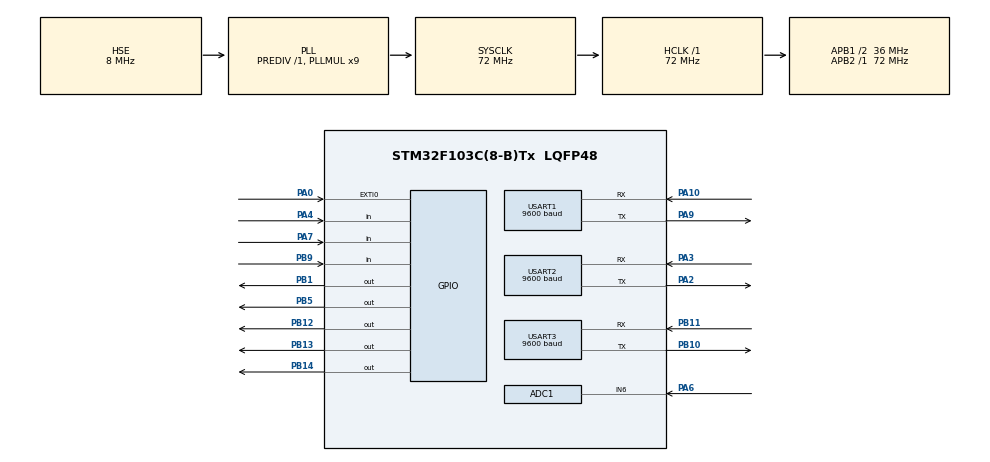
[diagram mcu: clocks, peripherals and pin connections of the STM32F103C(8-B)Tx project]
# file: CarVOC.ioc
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ADC1.Channel-0\#ChannelRegularConversion=ADC_CHANNEL_6
ADC1.ContinuousConvMode=DISABLE
ADC1.DataAlign=ADC_DATAALIGN_RIGHT
ADC1.DiscontinuousConvMode=DISABLE
ADC1.EnableAnalogWatchDog=false
ADC1.EnableRegularConversion=ENABLE
ADC1.ExternalTrigConv=ADC_SOFTWARE_START
ADC1.InjNumberOfConversion=0
ADC1.NbrOfConversion=1
ADC1.NbrOfConversionFlag=1
ADC1.Rank-0\#ChannelRegularConversion=1
ADC1.SamplingTime-0\#ChannelRegularConversion=ADC_SAMPLETIME_1CYCLE_5
ADC1.ScanConvMode=ADC_SCAN_DISABLE
ADC1.master=1
Dma.Request0=USART1_TX
Dma.Request1=USART2_TX
Dma.Request2=USART3_TX
Dma.USART1_TX.0.Direction=DMA_MEMORY_TO_PERIPH
Dma.USART1_TX.0.Instance=DMA1_Channel4
Dma.USART1_TX.0.MemDataAlignment=DMA_MDATAALIGN_BYTE
Dma.USART1_TX.0.MemInc=DMA_MINC_ENABLE
Dma.USART1_TX.0.Mode=DMA_NORMAL
Dma.USART1_TX.0.PeriphDataAlignment=DMA_PDATAALIGN_BYTE
Dma.USART1_TX.0.PeriphInc=DMA_PINC_DISABLE
Dma.USART1_TX.0.Priority=DMA_PRIORITY_MEDIUM
Dma.USART2_TX.1.Direction=DMA_MEMORY_TO_PERIPH
Dma.USART2_TX.1.Instance=DMA1_Channel7
Dma.USART2_TX.1.MemDataAlignment=DMA_MDATAALIGN_BYTE
Dma.USART2_TX.1.MemInc=DMA_MINC_ENABLE
Dma.USART2_TX.1.Mode=DMA_NORMAL
Dma.USART2_TX.1.PeriphDataAlignment=DMA_PDATAALIGN_BYTE
Dma.USART2_TX.1.PeriphInc=DMA_PINC_DISABLE
Dma.USART2_TX.1.Priority=DMA_PRIORITY_MEDIUM
Dma.USART3_TX.2.Direction=DMA_MEMORY_TO_PERIPH
Dma.USART3_TX.2.Instance=DMA1_Channel2
Dma.USART3_TX.2.MemDataAlignment=DMA_MDATAALIGN_BYTE
Dma.USART3_TX.2.MemInc=DMA_MINC_ENABLE
Dma.USART3_TX.2.Mode=DMA_NORMAL
Dma.USART3_TX.2.PeriphDataAlignment=DMA_PDATAALIGN_BYTE
Dma.USART3_TX.2.PeriphInc=DMA_PINC_DISABLE
Dma.USART3_TX.2.Priority=DMA_PRIORITY_MEDIUM
FREERTOS.Tasks01=defaultTask,0,128,StartDefaultTask,Default,NULL
FREERTOS.configTOTAL_HEAP_SIZE=13312
IWDG.Prescaler=IWDG_PRESCALER_8
IWDG.Reload=2500
Mcu.Family=STM32F1
Mcu.Name=STM32F103C(8-B)Tx
Mcu.Package=LQFP48
NVIC.DMA1_Channel2_IRQn=true\:5\:0\:false\:false\:true\:true\:false
NVIC.DMA1_Channel4_IRQn=true\:5\:0\:false\:false\:true\:true\:false
NVIC.DMA1_Channel7_IRQn=true\:5\:0\:false\:false\:true\:true\:false
NVIC.EXTI0_IRQn=true\:6\:0\:true\:true\:true\:1\:true\:true
NVIC.PriorityGroup=NVIC_PRIORITYGROUP_4
NVIC.TIM2_IRQn=true\:9\:0\:true\:true\:true\:5\:true\:true
NVIC.USART1_IRQn=true\:5\:0\:true\:true\:true\:3\:true\:true
NVIC.USART2_IRQn=true\:7\:0\:true\:true\:true\:4\:true\:true
NVIC.USART3_IRQn=true\:6\:0\:true\:true\:true\:6\:true\:true
PA0-WKUP.GPIO_ModeDefaultEXTI=GPIO_MODE_IT_RISING_FALLING
PA0-WKUP.GPIO_PuPd=GPIO_PULLUP
PA0-WKUP.Signal=GPXTI0
PA10.Mode=Asynchronous
PA10.Signal=USART1_RX
PA13.Mode=Trace_Asynchronous_SW
PA13.Signal=SYS_JTMS-SWDIO
PA14.Mode=Trace_Asynchronous_SW
PA14.Signal=SYS_JTCK-SWCLK
PA2.Mode=Asynchronous
PA2.Signal=USART2_TX
PA3.Mode=Asynchronous
PA3.Signal=USART2_RX
PA4.GPIO_PuPd=GPIO_PULLUP
PA4.Signal=GPIO_Input
PA6.Signal=ADCx_IN6
PA7.GPIO_PuPd=GPIO_PULLUP
PA7.Signal=GPIO_Input
PA9.Mode=Asynchronous
PA9.Signal=USART1_TX
PB1.GPIO_ModeDefaultOutputPP=GPIO_MODE_OUTPUT_PP
PB1.GPIO_PuPd=GPIO_NOPULL
PB1.GPIO_Speed=GPIO_SPEED_FREQ_MEDIUM
PB1.PinState=GPIO_PIN_RESET
PB1.Signal=GPIO_Output
PB10.Mode=Asynchronous
PB10.Signal=USART3_TX
PB11.Mode=Asynchronous
PB11.Signal=USART3_RX
PB12.GPIO_Speed=GPIO_SPEED_FREQ_MEDIUM
PB12.Signal=GPIO_Output
PB13.GPIO_Speed=GPIO_SPEED_FREQ_MEDIUM
PB13.Signal=GPIO_Output
PB14.GPIO_Speed=GPIO_SPEED_FREQ_MEDIUM
PB14.Signal=GPIO_Output
PB3.Mode=Trace_Asynchronous_SW
PB3.Signal=SYS_JTDO-TRACESWO
PB5.Signal=GPIO_Output
PB9.GPIO_PuPd=GPIO_PULLUP
PB9.Signal=GPIO_Input
PD0-OSC_IN.Mode=HSE-External-Oscillator
PD0-OSC_IN.Signal=RCC_OSC_IN
PD1-OSC_OUT.Mode=HSE-External-Oscillator
PD1-OSC_OUT.Signal=RCC_OSC_OUT
ProjectManager.HeapSize=0x200
ProjectManager.StackSize=0x400
ProjectManager.TargetToolchain=MDK-ARM V5
RCC.ADCPresc=RCC_ADCPCLK2_DIV6
RCC.AHBFreq_Value=72000000
RCC.APB1CLKDivider=RCC_HCLK_DIV2
RCC.APB1Freq_Value=36000000
RCC.APB1TimFreq_Value=72000000
RCC.APB2Freq_Value=72000000
RCC.APB2TimFreq_Value=72000000
RCC.HCLKFreq_Value=72000000
RCC.PLLMUL=RCC_PLL_MUL9
RCC.PLLSourceVirtual=RCC_PLLSOURCE_HSE
RCC.SYSCLKFreq_VALUE=72000000
RCC.SYSCLKSource=RCC_SYSCLKSOURCE_PLLCLK
RCC.USBFreq_Value=72000000
SH.ADCx_IN6.0=ADC1_IN6,IN6
TIM2.AutoReloadPreload=TIM_AUTORELOAD_PRELOAD_ENABLE
TIM2.Period=720-1
TIM2.Prescaler=1-1
USART1.BaudRate=9600
USART1.VirtualMode=VM_ASYNC
USART2.BaudRate=9600
USART2.VirtualMode=VM_ASYNC
USART3.BaudRate=9600
USART3.VirtualMode=VM_ASYNC
VP_FREERTOS_VS_ENABLE.Mode=Enabled
VP_IWDG_VS_IWDG.Mode=IWDG_Activate
VP_TIM2_VS_ClockSourceINT.Mode=Internal
board=MavSword

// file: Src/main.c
/**
  ******************************************************************************
  * @file           : main.c
  * @brief          : Main program body
  ******************************************************************************
  * This notice applies to any and all portions of this file
  * that are not between comment pairs USER CODE BEGIN and
  * USER CODE END. Other portions of this file, whether
  * inserted by the user or by software development tools
  * are owned by their respective copyright owners.
  *
  * Copyright (c) 2019 STMicroelectronics International N.V.
  * All rights reserved.
  *
  * Redistribution and use in source and binary forms, with or without
  * modification, are permitted, provided that the following conditions are met:
  *
  * 1. Redistribution of source code must retain the above copyright notice,
  *    this list of conditions and the following disclaimer.
  * 2. Redistributions in binary form must reproduce the above copyright notice,
  *    this list of conditions and the following disclaimer in the documentation
  *    and/or other materials provided with the distribution.
  * 3. Neither the name of STMicroelectronics nor the names of other
  *    contributors to this software may be used to endorse or promote products
  *    derived from this software without specific written permission.
  * 4. This software, including modifications and/or derivative works of this
  *    software, must execute solely and exclusively on microcontroller or
  *    microprocessor devices manufactured by or for STMicroelectronics.
  * 5. Redistribution and use of this software other than as permitted under
  *    this license is void and will automatically terminate your rights under
  *    this license.
  *
  * THIS SOFTWARE IS PROVIDED BY STMICROELECTRONICS AND CONTRIBUTORS "AS IS"
  * AND ANY EXPRESS, IMPLIED OR STATUTORY WARRANTIES, INCLUDING, BUT NOT
  * LIMITED TO, THE IMPLIED WARRANTIES OF MERCHANTABILITY, FITNESS FOR A
  * PARTICULAR PURPOSE AND NON-INFRINGEMENT OF THIRD PARTY INTELLECTUAL PROPERTY
  * RIGHTS ARE DISCLAIMED TO THE FULLEST EXTENT PERMITTED BY LAW. IN NO EVENT
  * SHALL STMICROELECTRONICS OR CONTRIBUTORS BE LIABLE FOR ANY DIRECT, INDIRECT,
  * INCIDENTAL, SPECIAL, EXEMPLARY, OR CONSEQUENTIAL DAMAGES (INCLUDING, BUT NOT
  * LIMITED TO, PROCUREMENT OF SUBSTITUTE GOODS OR SERVICES; LOSS OF USE, DATA,
  * OR PROFITS; OR BUSINESS INTERRUPTION) HOWEVER CAUSED AND ON ANY THEORY OF
  * LIABILITY, WHETHER IN CONTRACT, STRICT LIABILITY, OR TORT (INCLUDING
  * NEGLIGENCE OR OTHERWISE) ARISING IN ANY WAY OUT OF THE USE OF THIS SOFTWARE,
  * EVEN IF ADVISED OF THE POSSIBILITY OF SUCH DAMAGE.
  *
  ******************************************************************************
  */
#include "main.h"
#include "stm32f1xx_hal.h"
#include "cmsis_os.h"

/* USER CODE BEGIN Includes */
#include "UserTask.h"
/* USER CODE END Includes */

ADC_HandleTypeDef hadc1;

IWDG_HandleTypeDef hiwdg;

TIM_HandleTypeDef htim2;

UART_HandleTypeDef huart1;
UART_HandleTypeDef huart2;
UART_HandleTypeDef huart3;
DMA_HandleTypeDef hdma_usart1_tx;
DMA_HandleTypeDef hdma_usart2_tx;
DMA_HandleTypeDef hdma_usart3_tx;

osThreadId defaultTaskHandle;

/* USER CODE BEGIN PV */
/* Private variables ---------------------------------------------------------*/

/* USER CODE END PV */

void SystemClock_Config(void);
static void MX_GPIO_Init(void);
static void MX_DMA_Init(void);
static void MX_USART1_UART_Init(void);
static void MX_USART2_UART_Init(void);
static void MX_IWDG_Init(void);
static void MX_TIM2_Init(void);
static void MX_USART3_UART_Init(void);
static void MX_ADC1_Init(void);
void StartDefaultTask(void const * argument);
static void MX_NVIC_Init(void);

/* USER CODE BEGIN PFP */
/* Private function prototypes -----------------------------------------------*/

/* USER CODE END PFP */

int main(void)
{

  /* MCU Configuration----------------------------------------------------------*/

  /* Reset of all peripherals, Initializes the Flash interface and the Systick. */
  HAL_Init();

  /* Configure the system clock */
  SystemClock_Config();

  /* Initialize all configured peripherals */
  MX_GPIO_Init();
  MX_DMA_Init();
  MX_USART1_UART_Init();
  MX_USART2_UART_Init();
  MX_IWDG_Init();
  MX_TIM2_Init();
  MX_USART3_UART_Init();
  MX_ADC1_Init();

  /* Initialize interrupts */
  MX_NVIC_Init();

  /* Create the thread(s) */
  /* definition and creation of defaultTask */
  osThreadDef(defaultTask, StartDefaultTask, osPriorityNormal, 0, 128);
  defaultTaskHandle = osThreadCreate(osThread(defaultTask), NULL);

  /* USER CODE BEGIN RTOS_THREADS */
  /* add threads, ... */
	app_run();
  /* USER CODE END RTOS_THREADS */

  /* Start scheduler */
  osKernelStart();

  /* We should never get here as control is now taken by the scheduler */

  /* Infinite loop */
  while (1)
  {

  }

}

void SystemClock_Config(void)
{

  RCC_OscInitTypeDef RCC_OscInitStruct;
  RCC_ClkInitTypeDef RCC_ClkInitStruct;
  RCC_PeriphCLKInitTypeDef PeriphClkInit;

    /**Initializes the CPU, AHB and APB busses clocks
    */
  RCC_OscInitStruct.OscillatorType = RCC_OSCILLATORTYPE_LSI|RCC_OSCILLATORTYPE_HSE;
  RCC_OscInitStruct.HSEState = RCC_HSE_ON;
  RCC_OscInitStruct.HSEPredivValue = RCC_HSE_PREDIV_DIV1;
  RCC_OscInitStruct.HSIState = RCC_HSI_ON;
  RCC_OscInitStruct.LSIState = RCC_LSI_ON;
  RCC_OscInitStruct.PLL.PLLState = RCC_PLL_ON;
  RCC_OscInitStruct.PLL.PLLSource = RCC_PLLSOURCE_HSE;
  RCC_OscInitStruct.PLL.PLLMUL = RCC_PLL_MUL9;
  if (HAL_RCC_OscConfig(&RCC_OscInitStruct) != HAL_OK)
  {
    _Error_Handler(__FILE__, __LINE__);
  }

    /**Initializes the CPU, AHB and APB busses clocks
    */
  RCC_ClkInitStruct.ClockType = RCC_CLOCKTYPE_HCLK|RCC_CLOCKTYPE_SYSCLK
                              |RCC_CLOCKTYPE_PCLK1|RCC_CLOCKTYPE_PCLK2;
  RCC_ClkInitStruct.SYSCLKSource = RCC_SYSCLKSOURCE_PLLCLK;
  RCC_ClkInitStruct.AHBCLKDivider = RCC_SYSCLK_DIV1;
  RCC_ClkInitStruct.APB1CLKDivider = RCC_HCLK_DIV2;
  RCC_ClkInitStruct.APB2CLKDivider = RCC_HCLK_DIV1;

  if (HAL_RCC_ClockConfig(&RCC_ClkInitStruct, FLASH_LATENCY_2) != HAL_OK)
  {
    _Error_Handler(__FILE__, __LINE__);
  }

  PeriphClkInit.PeriphClockSelection = RCC_PERIPHCLK_ADC;
  PeriphClkInit.AdcClockSelection = RCC_ADCPCLK2_DIV6;
  if (HAL_RCCEx_PeriphCLKConfig(&PeriphClkInit) != HAL_OK)
  {
    _Error_Handler(__FILE__, __LINE__);
  }

    /**Configure the Systick interrupt time
    */
  HAL_SYSTICK_Config(HAL_RCC_GetHCLKFreq()/1000);

    /**Configure the Systick
    */
  HAL_SYSTICK_CLKSourceConfig(SYSTICK_CLKSOURCE_HCLK);

  /* SysTick_IRQn interrupt configuration */
  HAL_NVIC_SetPriority(SysTick_IRQn, 15, 0);
}

/**
  * @brief NVIC Configuration.
  * @retval None
  */
static void MX_NVIC_Init(void)
{
  /* EXTI0_IRQn interrupt configuration */
  HAL_NVIC_SetPriority(EXTI0_IRQn, 6, 0);
  HAL_NVIC_EnableIRQ(EXTI0_IRQn);
  /* USART1_IRQn interrupt configuration */
  HAL_NVIC_SetPriority(USART1_IRQn, 5, 0);
  HAL_NVIC_EnableIRQ(USART1_IRQn);
  /* USART2_IRQn interrupt configuration */
  HAL_NVIC_SetPriority(USART2_IRQn, 7, 0);
  HAL_NVIC_EnableIRQ(USART2_IRQn);
  /* TIM2_IRQn interrupt configuration */
  HAL_NVIC_SetPriority(TIM2_IRQn, 9, 0);
  HAL_NVIC_EnableIRQ(TIM2_IRQn);
  /* USART3_IRQn interrupt configuration */
  HAL_NVIC_SetPriority(USART3_IRQn, 6, 0);
  HAL_NVIC_EnableIRQ(USART3_IRQn);
}

/* ADC1 init function */
static void MX_ADC1_Init(void)
{

  ADC_ChannelConfTypeDef sConfig;

    /**Common config
    */
  hadc1.Instance = ADC1;
  hadc1.Init.ScanConvMode = ADC_SCAN_DISABLE;
  hadc1.Init.ContinuousConvMode = DISABLE;
  hadc1.Init.DiscontinuousConvMode = DISABLE;
  hadc1.Init.ExternalTrigConv = ADC_SOFTWARE_START;
  hadc1.Init.DataAlign = ADC_DATAALIGN_RIGHT;
  hadc1.Init.NbrOfConversion = 1;
  if (HAL_ADC_Init(&hadc1) != HAL_OK)
  {
    _Error_Handler(__FILE__, __LINE__);
  }

    /**Configure Regular Channel
    */
  sConfig.Channel = ADC_CHANNEL_6;
  sConfig.Rank = ADC_REGULAR_RANK_1;
  sConfig.SamplingTime = ADC_SAMPLETIME_1CYCLE_5;
  if (HAL_ADC_ConfigChannel(&hadc1, &sConfig) != HAL_OK)
  {
    _Error_Handler(__FILE__, __LINE__);
  }

}

/* IWDG init function */
static void MX_IWDG_Init(void)
{

  hiwdg.Instance = IWDG;
  hiwdg.Init.Prescaler = IWDG_PRESCALER_8;
  hiwdg.Init.Reload = 2500;
  if (HAL_IWDG_Init(&hiwdg) != HAL_OK)
  {
    _Error_Handler(__FILE__, __LINE__);
  }

}

/* TIM2 init function */
static void MX_TIM2_Init(void)
{

  TIM_ClockConfigTypeDef sClockSourceConfig;
  TIM_MasterConfigTypeDef sMasterConfig;

  htim2.Instance = TIM2;
  htim2.Init.Prescaler = 1-1;
  htim2.Init.CounterMode = TIM_COUNTERMODE_UP;
  htim2.Init.Period = 720-1;
  htim2.Init.ClockDivision = TIM_CLOCKDIVISION_DIV1;
  htim2.Init.AutoReloadPreload = TIM_AUTORELOAD_PRELOAD_ENABLE;
  if (HAL_TIM_Base_Init(&htim2) != HAL_OK)
  {
    _Error_Handler(__FILE__, __LINE__);
  }

  sClockSourceConfig.ClockSource = TIM_CLOCKSOURCE_INTERNAL;
  if (HAL_TIM_ConfigClockSource(&htim2, &sClockSourceConfig) != HAL_OK)
  {
    _Error_Handler(__FILE__, __LINE__);
  }

  sMasterConfig.MasterOutputTrigger = TIM_TRGO_RESET;
  sMasterConfig.MasterSlaveMode = TIM_MASTERSLAVEMODE_DISABLE;
  if (HAL_TIMEx_MasterConfigSynchronization(&htim2, &sMasterConfig) != HAL_OK)
  {
    _Error_Handler(__FILE__, __LINE__);
  }

}

/* USART1 init function */
static void MX_USART1_UART_Init(void)
{

  huart1.Instance = USART1;
  huart1.Init.BaudRate = 9600;
  huart1.Init.WordLength = UART_WORDLENGTH_8B;
  huart1.Init.StopBits = UART_STOPBITS_1;
  huart1.Init.Parity = UART_PARITY_NONE;
  huart1.Init.Mode = UART_MODE_TX_RX;
  huart1.Init.HwFlowCtl = UART_HWCONTROL_NONE;
  huart1.Init.OverSampling = UART_OVERSAMPLING_16;
  if (HAL_UART_Init(&huart1) != HAL_OK)
  {
    _Error_Handler(__FILE__, __LINE__);
  }

}

/* USART2 init function */
static void MX_USART2_UART_Init(void)
{

  huart2.Instance = USART2;
  huart2.Init.BaudRate = 9600;
  huart2.Init.WordLength = UART_WORDLENGTH_8B;
  huart2.Init.StopBits = UART_STOPBITS_1;
  huart2.Init.Parity = UART_PARITY_NONE;
  huart2.Init.Mode = UART_MODE_TX_RX;
  huart2.Init.HwFlowCtl = UART_HWCONTROL_NONE;
  huart2.Init.OverSampling = UART_OVERSAMPLING_16;
  if (HAL_UART_Init(&huart2) != HAL_OK)
  {
    _Error_Handler(__FILE__, __LINE__);
  }

}

/* USART3 init function */
static void MX_USART3_UART_Init(void)
{

  huart3.Instance = USART3;
  huart3.Init.BaudRate = 9600;
  huart3.Init.WordLength = UART_WORDLENGTH_8B;
  huart3.Init.StopBits = UART_STOPBITS_1;
  huart3.Init.Parity = UART_PARITY_NONE;
  huart3.Init.Mode = UART_MODE_TX_RX;
  huart3.Init.HwFlowCtl = UART_HWCONTROL_NONE;
  huart3.Init.OverSampling = UART_OVERSAMPLING_16;
  if (HAL_UART_Init(&huart3) != HAL_OK)
  {
    _Error_Handler(__FILE__, __LINE__);
  }

}

static void MX_DMA_Init(void)
{
  /* DMA controller clock enable */
  __HAL_RCC_DMA1_CLK_ENABLE();

  /* DMA interrupt init */
  /* DMA1_Channel2_IRQn interrupt configuration */
  HAL_NVIC_SetPriority(DMA1_Channel2_IRQn, 5, 0);
  HAL_NVIC_EnableIRQ(DMA1_Channel2_IRQn);
  /* DMA1_Channel4_IRQn interrupt configuration */
  HAL_NVIC_SetPriority(DMA1_Channel4_IRQn, 5, 0);
  HAL_NVIC_EnableIRQ(DMA1_Channel4_IRQn);
  /* DMA1_Channel7_IRQn interrupt configuration */
  HAL_NVIC_SetPriority(DMA1_Channel7_IRQn, 5, 0);
  HAL_NVIC_EnableIRQ(DMA1_Channel7_IRQn);

}

/** Configure pins as
        * Analog
        * Input
        * Output
        * EVENT_OUT
        * EXTI
*/
static void MX_GPIO_Init(void)
{

  GPIO_InitTypeDef GPIO_InitStruct;

  /* GPIO Ports Clock Enable */
  __HAL_RCC_GPIOD_CLK_ENABLE();
  __HAL_RCC_GPIOA_CLK_ENABLE();
  __HAL_RCC_GPIOB_CLK_ENABLE();

  /*Configure GPIO pin Output Level */
  HAL_GPIO_WritePin(GPIOB, GPIO_PIN_1|GPIO_PIN_12|GPIO_PIN_13|GPIO_PIN_14
                          |GPIO_PIN_5, GPIO_PIN_RESET);

  /*Configure GPIO pin : PA0 */
  GPIO_InitStruct.Pin = GPIO_PIN_0;
  GPIO_InitStruct.Mode = GPIO_MODE_IT_RISING_FALLING;
  GPIO_InitStruct.Pull = GPIO_PULLUP;
  HAL_GPIO_Init(GPIOA, &GPIO_InitStruct);

  /*Configure GPIO pins : PA4 PA7 */
  GPIO_InitStruct.Pin = GPIO_PIN_4|GPIO_PIN_7;
  GPIO_InitStruct.Mode = GPIO_MODE_INPUT;
  GPIO_InitStruct.Pull = GPIO_PULLUP;
  HAL_GPIO_Init(GPIOA, &GPIO_InitStruct);

  /*Configure GPIO pins : PB1 PB12 PB13 PB14 */
  GPIO_InitStruct.Pin = GPIO_PIN_1|GPIO_PIN_12|GPIO_PIN_13|GPIO_PIN_14;
  GPIO_InitStruct.Mode = GPIO_MODE_OUTPUT_PP;
  GPIO_InitStruct.Pull = GPIO_NOPULL;
  GPIO_InitStruct.Speed = GPIO_SPEED_FREQ_MEDIUM;
  HAL_GPIO_Init(GPIOB, &GPIO_InitStruct);

  /*Configure GPIO pin : PB5 */
  GPIO_InitStruct.Pin = GPIO_PIN_5;
  GPIO_InitStruct.Mode = GPIO_MODE_OUTPUT_PP;
  GPIO_InitStruct.Pull = GPIO_NOPULL;
  GPIO_InitStruct.Speed = GPIO_SPEED_FREQ_LOW;
  HAL_GPIO_Init(GPIOB, &GPIO_InitStruct);

  /*Configure GPIO pin : PB9 */
  GPIO_InitStruct.Pin = GPIO_PIN_9;
  GPIO_InitStruct.Mode = GPIO_MODE_INPUT;
  GPIO_InitStruct.Pull = GPIO_PULLUP;
  HAL_GPIO_Init(GPIOB, &GPIO_InitStruct);

}

void StartDefaultTask(void const * argument)
{

  for(;;)
  {
    osDelay(1);
  }
}

void _Error_Handler(char *file, int line)
{
  while(1)
  {
  }
}

/************************ (C) COPYRIGHT STMicroelectronics *****END OF FILE****/
